# SAM9X60 device description
Architecture: ARM926EJS; Family: SAM9; Series: SAM9X
Registers are 32-bit, read-write, no defined reset value unless marked. A register's access mark holds for its fields unless they carry their own. Offsets are from the block's base; [hi:lo] are bit positions; {n}, {i} and the like mark numbered series.

## UHPHS — USB Host High Speed Port
Instances: UHPHS_EHCI 0x00700000
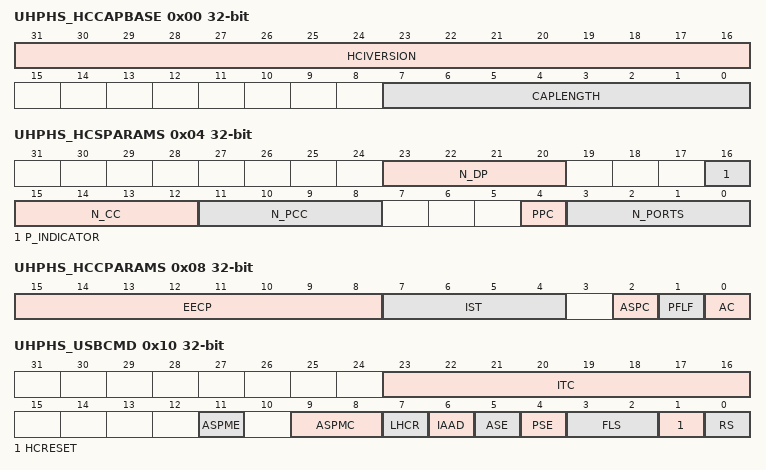
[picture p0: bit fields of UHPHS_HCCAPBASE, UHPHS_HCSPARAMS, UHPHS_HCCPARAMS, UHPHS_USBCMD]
0x00 UHPHS_HCCAPBASE ro — UHPHS Host Controller Capability Register
  [31:16] HCIVERSION — Host Controller Interface Version Number
  [7:0] CAPLENGTH — Capability Registers Length
0x04 UHPHS_HCSPARAMS ro — UHPHS Host Controller Structural Parameters Register
  [23:20] N_DP — Debug Port Number
  [16] P_INDICATOR — Port Indicators
  [15:12] N_CC — Number of Companion Controllers
  [11:8] N_PCC — Number of Ports per Companion Controller
  [4] PPC — Port Power Control
  [3:0] N_PORTS — Number of Ports
0x08 UHPHS_HCCPARAMS ro — UHPHS Host Controller Capability Parameters Register
  [15:8] EECP — EHCI Extended Capabilities Pointer
  [7:4] IST — Isochronous Scheduling Threshold
  [2] ASPC — Asynchronous Schedule Park Capability
  [1] PFLF — Programmable Frame List Flag
  [0] AC — 64-bit Addressing Capability
0x10 UHPHS_USBCMD — UHPHS USB Command Register
  [23:16] ITC — Interrupt Threshold Control (read/write)
  [11] ASPME — Asynchronous Schedule Park Mode Enable (optional) (read/write or read-only)
  [9:8] ASPMC — Asynchronous Schedule Park Mode Count (optional) (read/write or read-only)
  [7] LHCR — Light Host Controller Reset (optional) (read/write)
  [6] IAAD — Interrupt on Async Advance Doorbell (read/write)
  [5] ASE — Asynchronous Schedule Enable (read/write)
  [4] PSE — Periodic Schedule Enable (read/write)
  [3:2] FLS — Frame List Size (read/write or read-only)
  [1] HCRESET — Host Controller Reset (read/write)
  [0] RS — Run/Stop (read/write)
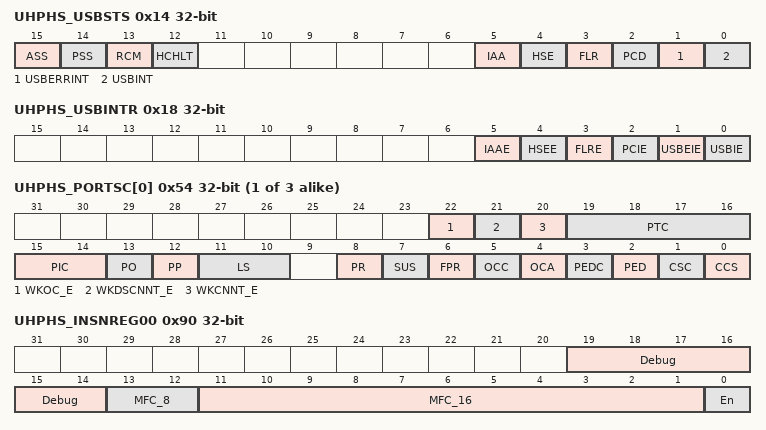
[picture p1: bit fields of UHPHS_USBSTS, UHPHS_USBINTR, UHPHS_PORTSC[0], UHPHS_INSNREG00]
0x14 UHPHS_USBSTS — UHPHS USB Status Register
  [15] ASS — Asynchronous Schedule Status (read-only)
  [14] PSS — Periodic Schedule Status (read-only)
  [13] RCM — Reclamation (read-only)
  [12] HCHLT — HCHalted (read-only)
  [5] IAA — Interrupt on Async Advance (cleared on write)
  [4] HSE — Host System Error (cleared on write)
  [3] FLR — Frame List Rollover (cleared on write)
  [2] PCD — Port Change Detect (cleared on write)
  [1] USBERRINT — USB Error Interrupt (cleared on write)
  [0] USBINT — USB Interrupt (cleared on write)
0x18 UHPHS_USBINTR — UHPHS USB Interrupt Enable Register
  [5] IAAE — Interrupt on Async Advance Enable
  [4] HSEE — Host System Error Interrupt Enable
  [3] FLRE — Frame List Rollover Interrupt Enable
  [2] PCIE — Port Change Detect Interrupt Enable
  [1] USBEIE — USBERRINT Interrupt Enable
  [0] USBIE — USBINT Interrupt Enable
0x1C UHPHS_FRINDEX — UHPHS USB Frame Index Register
  [13:0] FI — Frame Index
0x20 UHPHS_CTRLDSSEGMENT — UHPHS Control Data Structure Segment Register
0x24 UHPHS_PERIODICLISTBASE — UHPHS Periodic Frame List Base Address Register
  [31:12] BA — Base Address (Low)
0x28 UHPHS_ASYNCLISTADDR — UHPHS Asynchronous List Address Register
  [31:5] LPL — Link Pointer Low
0x50 UHPHS_CONFIGFLAG — UHPHS Configured Flag Register
  [0] CF — Configure Flag (Read/Write)
{0x54+4i} UHPHS_PORTSC[{i}] (i=0..2) — UHPHS Port Status and Control Register (port = 0)
  [22] WKOC_E — Wake on Over-current Enable (read/write)
  [21] WKDSCNNT_E — Wake on Disconnect Enable (read/write)
  [20] WKCNNT_E — Wake on Connect Enable (read/write)
  [19:16] PTC — Port Test Control (read/write)
  [15:14] PIC — Port Indicator Control (read/write)
  [13] PO — Port Owner (read/write)
  [12] PP — Port Power (read/write or read-only)
  [11:10] LS — Line Status (read-only)
    0=SE0 (Not a low-speed device, perform EHCI reset); 1=K_STATE (Low-speed device, release ownership of port); 2=J_STATE (Not a low-speed device, perform EHCI reset); 3=UNDEFINED (Not a low-speed device, perform EHCI reset)
  [8] PR — Port Reset (read/write)
  [7] SUS — Suspend (read/write)
  [6] FPR — Force Port Resume (read/write)
  [5] OCC — Over-current Change (read/write clear)
  [4] OCA — Over-current Active (read-only)
  [3] PEDC — Port Enable/Disable Change (read/write clear)
  [2] PED — Port Enabled/Disabled (read/write)
  [1] CSC — Connect Status Change (read/write clear)
  [0] CCS — Current Connect Status (read-only)
0x90 UHPHS_INSNREG00 — EHCI Specific Registers 00
  [19:14] Debug — Debug Purposes
  [13:12] MFC_8 — Microframe Counter with Byte Interface
  [11:1] MFC_16 — Microframe Counter with Word Byte Interface
  [0] En — Enable Programmable Microframe Base Value
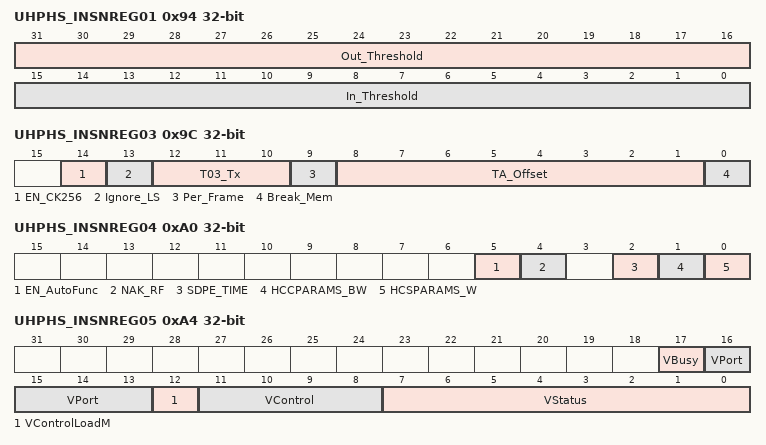
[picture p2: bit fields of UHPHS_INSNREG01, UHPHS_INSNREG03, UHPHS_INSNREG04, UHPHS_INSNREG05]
0x94 UHPHS_INSNREG01 — EHCI Specific Registers 01
  [31:16] Out_Threshold — Amount of Data Available in the OUT Packet Buffer
  [15:0] In_Threshold — Amount of Data Available in the IN Packet Buffer
0x98 UHPHS_INSNREG02 — EHCI Specific Registers 02
  [11:0] Dwords — Number of Entries
0x9C UHPHS_INSNREG03 — EHCI Specific Registers 03
  [14] EN_CK256 — Enable 256 Clock Checking
  [13] Ignore_LS — Ignore Linestate During TestSE0 NAK
  [12:10] T03_Tx — Transmit to Transmit Turnaround Delay Add-on
  [9] Per_Frame — Periodic Frame List Fetch
  [8:1] TA_Offset — Time-Available Offset
  [0] Break_Mem — Break Memory Transfer (in CONFIG1 mode only, not applicable in CONFIG2 mode)
0xA0 UHPHS_INSNREG04 — EHCI Specific Registers 04
  [5] EN_AutoFunc — Enable Automatic Feature
  [4] NAK_RF — NAK Reload Fix (Read/Write)
  [2] SDPE_TIME — Scales Down Port Enumeration Time
  [1] HCCPARAMS_BW — HCCPARAMS Bits Write
  [0] HCSPARAMS_W — HCSPARAMS Write
0xA4 UHPHS_INSNREG05 — EHCI Specific Registers 05
  [17] VBusy — Vendor Busy (Read-only)
  [16:13] VPort — Vendor Port (Read/Write)
  [12] VControlLoadM — Vendor Control Load Microframe (Read/Write)
  [11:8] VControl — Vendor Control (Read/Write)
  [7:0] VStatus — Vendor Status (Read-only)
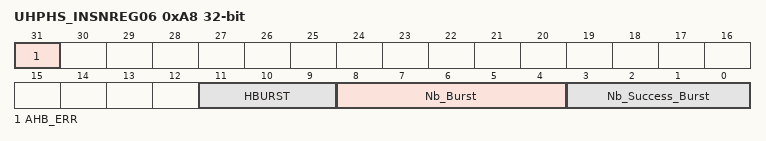
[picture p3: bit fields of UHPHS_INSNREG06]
0xA8 UHPHS_INSNREG06 — EHCI Specific Registers 06
  [31] AHB_ERR — AHB Error
  [11:9] HBURST — Burst Value (Read-only)(1)
  [8:4] Nb_Burst — Number of Bursts (Read-only)(1)
  [3:0] Nb_Success_Burst — Number of Successful Bursts (Read-only)(1)
0xAC UHPHS_INSNREG07 — EHCI Specific Registers 07
  [31:0] AHB_ADDR — AHB Address (Read Only)
